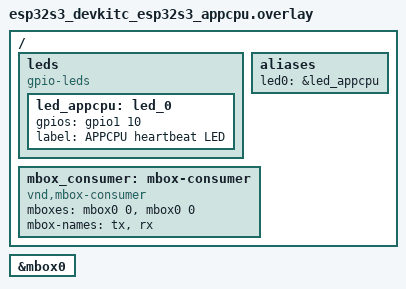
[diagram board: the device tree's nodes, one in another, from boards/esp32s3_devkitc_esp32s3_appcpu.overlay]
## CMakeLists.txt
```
cmake_minimum_required(VERSION 3.20.0)

find_package(Zephyr REQUIRED HINTS $ENV{ZEPHYR_BASE})
project(03_shm_race_appcpu)

target_sources(app PRIVATE src/main.c)
```

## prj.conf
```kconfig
# 03_SHM_RACE_LAB - core1 (appcpu) image
#
# No CONFIG_LOG / console here on purpose - see 01_HELLO_DUALCORE_LAB's
# doc for why (no UART console support on the appcpu image in Zephyr yet).
# This core proves what it's doing entirely through its heartbeat LED.
#
# NOTE: &ipm0 is intentionally left DISABLED - see prj.conf in the procpu
# app for why (only one of ipm0/mbox0 is ever enabled per lab).

CONFIG_GPIO=y
CONFIG_MBOX=y
```

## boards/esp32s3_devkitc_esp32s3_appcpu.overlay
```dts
/*
 * Overlay for 03_SHM_RACE_LAB - core1 (appcpu) image
 *
 * Reuses this series' GPIO42 "led0" heartbeat LED convention (see Lab 01).
 * See the procpu overlay in this same lab for why no new devicetree node
 * is needed for shared memory (ipmmem0 reuse) and why only &mbox0 (not
 * &ipm0) is enabled here.
 */

#include <zephyr/dt-bindings/gpio/gpio.h>

/ {
    leds {
        compatible = "gpio-leds";
        led_appcpu: led_0 {
            gpios = <&gpio1 10 GPIO_ACTIVE_HIGH>;
            label = "APPCPU heartbeat LED";
        };
    };

    aliases {
        led0 = &led_appcpu;
    };

    mbox_consumer: mbox-consumer {
        compatible = "vnd,mbox-consumer";
        mboxes = <&mbox0 0>, <&mbox0 0>;
        mbox-names = "tx", "rx";
    };
};

&mbox0 {
    status = "okay";
};
```

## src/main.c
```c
/*
 * main.c - 03_SHM_RACE_LAB (core1 / appcpu image)
 *
 * No console here (see 01_HELLO_DUALCORE_LAB's doc for why) - this core's
 * only visible output is its heartbeat LED (GPIO42):
 *
 *   - Normally blinks at a steady 200ms rate, same as Labs 01/02.
 *   - Every time it finishes "processing" one backlog item (see below), it
 *     does a quick double-flash before returning to its normal blink.
 *
 * The actual lesson of this lab happens where you can't see it directly on
 * this core (no console) but CAN see it in procpu's serial log: this core
 * deliberately processes backlog items more slowly (PROCESS_PERIOD_MS)
 * than procpu sends them (SEND_PERIOD_MS in the procpu image), so a
 * backlog builds up. An atomic pending-counter (see "pending" below) makes
 * sure every single doorbell procpu rings is still *counted* even while
 * this core is busy - but because procpu keeps overwriting the SAME
 * shared-memory slot with newer values the whole time, by the time this
 * core gets around to reading it, several intermediate values are already
 * gone for good. That gap is the point: counting notifications correctly
 * (atomic_t) is not the same problem as not losing the DATA that came with
 * each one - see the doc.
 */

#include <zephyr/kernel.h>
#include <zephyr/drivers/gpio.h>
#include <zephyr/drivers/mbox.h>
#include <zephyr/sys/atomic.h>

#include "shared_mem.h"

static const struct gpio_dt_spec led = GPIO_DT_SPEC_GET(DT_ALIAS(led0), gpios);

static const struct mbox_dt_spec tx_channel = MBOX_DT_SPEC_GET(DT_PATH(mbox_consumer), tx);
static const struct mbox_dt_spec rx_channel = MBOX_DT_SPEC_GET(DT_PATH(mbox_consumer), rx);

#define BLINK_PERIOD_MS       200
#define REACT_FLASH_PERIOD_MS 80
#define REACT_FLASH_EDGES     4 /* 4 edges = 2 full on/off flashes */

/* Deliberately slower than procpu's SEND_PERIOD_MS (200ms) - this gap is
 * what causes the backlog / lost-values race this lab demonstrates.
 */
#define PROCESS_PERIOD_MS 350
#define POLL_PERIOD_MS    10

/*
 * Incremented from ISR context on every doorbell from procpu. See the
 * procpu image's main.c for why atomic_t (not a plain bool/int) matters
 * here: it guarantees this core eventually finds out about and processes
 * every single doorbell, even ones that arrive while it is still busy
 * with an earlier one.
 */
static atomic_t pending = ATOMIC_INIT(0);

static void doorbell_from_procpu(const struct device *dev, mbox_channel_id_t channel_id,
				  void *user_data, struct mbox_msg *data)
{
	ARG_UNUSED(dev);
	ARG_UNUSED(channel_id);
	ARG_UNUSED(user_data);
	ARG_UNUSED(data);

	atomic_inc(&pending);
}

int main(void)
{
	if (!gpio_is_ready_dt(&led)) {
		return -1;
	}

	if (gpio_pin_configure_dt(&led, GPIO_OUTPUT_INACTIVE)) {
		return -1;
	}

	mbox_register_callback_dt(&rx_channel, doorbell_from_procpu, NULL);
	mbox_set_enabled_dt(&rx_channel, true);

	bool led_state = false;
	int64_t next_toggle = k_uptime_get() + BLINK_PERIOD_MS;
	int64_t next_process = 0; /* ready to process immediately */
	int reaction_edges_remaining = 0;
	uint32_t drained_count = 0;

	volatile struct p2a_payload *p2a = (volatile struct p2a_payload *)SHM_P2A_ADDR;
	volatile struct a2p_payload *a2p = (volatile struct a2p_payload *)SHM_A2P_ADDR;

	while (1) {
		int64_t now = k_uptime_get();

		/*
		 * Process at most one backlog item per PROCESS_PERIOD_MS,
		 * without ever blocking this loop - the LED heartbeat below
		 * keeps running on its own independent schedule regardless
		 * of backlog size.
		 */
		if (now >= next_process && atomic_get(&pending) > 0) {
			atomic_dec(&pending);
			drained_count++;

			/*
			 * Read whatever value happens to be in shared memory
			 * right now - NOT necessarily the value that was
			 * current when THIS particular doorbell was rung,
			 * since procpu may have already overwritten it one or
			 * more times since then.
			 */
			uint32_t seen_seq = p2a->seq;

			a2p->drained_count = drained_count;
			a2p->last_seen_seq = seen_seq;
			mbox_send_dt(&tx_channel, NULL);

			reaction_edges_remaining = REACT_FLASH_EDGES;
			next_process = now + PROCESS_PERIOD_MS;
		}

		if (reaction_edges_remaining > 0) {
			if (now >= next_toggle) {
				led_state = !led_state;
				gpio_pin_set_dt(&led, led_state);
				reaction_edges_remaining--;
				next_toggle = now + REACT_FLASH_PERIOD_MS;
			}
		} else if (now >= next_toggle) {
			led_state = !led_state;
			gpio_pin_set_dt(&led, led_state);
			next_toggle = now + BLINK_PERIOD_MS;
		}

		k_msleep(POLL_PERIOD_MS);
	}

	return 0;
}
```

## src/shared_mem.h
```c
/*
 * shared_mem.h - 03_SHM_RACE_LAB
 *
 * Describes the raw memory layout this lab uses inside ipmmem0, the 1KB
 * SRAM block (physical address 0x3fce5000) that the SoC devicetree already
 * reserves as &ipm0/&mbox0's own private message-copy scratch buffer (see
 * the "shared-memory"/"shared-memory-size" properties on those nodes in
 * Zephyr's esp32s3_common.dtsi). This lab reuses that exact block instead
 * of asking for a brand-new reserved-memory region, because every
 * mbox_send_dt() call this lab makes always passes a NULL payload (a pure
 * signal, same as 02_MBOX_DOORBELL_LAB) - so the mbox0 driver's own
 * memcpy into this buffer (drivers/mbox/mbox_esp32.c) is never triggered,
 * and the whole block is free for this lab's own use. See the doc for the
 * full reasoning.
 *
 * This file is intentionally duplicated byte-for-byte between src/ and
 * remote/src/ rather than shared through a common include path, because
 * procpu and appcpu are two completely separate Zephyr applications
 * (separate CMakeLists.txt / project() calls) built for two different
 * boards - keeping one small header in sync by hand is simpler here than
 * wiring up a shared include directory between them. If you edit this
 * file, edit both copies.
 */

#ifndef SHARED_MEM_H_
#define SHARED_MEM_H_

#include <zephyr/devicetree.h>
#include <stdint.h>

/* Base address/size of the reused ipmmem0 block, read directly from the
 * devicetree node - no application-defined devicetree node is needed for
 * this, since ipmmem0 is already declared (unconditionally) at the SoC
 * level and its "reg" property is readable via its label regardless of
 * whether &ipm0/&mbox0 are enabled. */
#define SHM_BASE (DT_REG_ADDR(DT_NODELABEL(ipmmem0)))
#define SHM_SIZE (DT_REG_SIZE(DT_NODELABEL(ipmmem0)))

/* mbox0's own driver splits this same 1KB block into two halves, one per
 * direction (see pro_cpu_shm/app_cpu_shm in drivers/mbox/mbox_esp32.c).
 * We mirror that same split for our own traffic, purely for symmetry. */
#define SHM_HALF_SIZE (SHM_SIZE / 2)

/* procpu writes here, appcpu reads (procpu -> appcpu) */
#define SHM_P2A_ADDR (SHM_BASE)
/* appcpu writes here, procpu reads (appcpu -> procpu) */
#define SHM_A2P_ADDR (SHM_BASE + SHM_HALF_SIZE)

/* procpu -> appcpu: one monotonically increasing sequence number per send */
struct p2a_payload {
	uint32_t seq;
};

/* appcpu -> procpu: what appcpu actually managed to process */
struct a2p_payload {
	uint32_t drained_count; /* total backlog items processed so far */
	uint32_t last_seen_seq; /* whatever seq value was in SHM_P2A_ADDR at
				  * the moment this item was processed - NOT
				  * guaranteed to include every value procpu
				  * ever wrote (see the doc)
				  */
};

#endif /* SHARED_MEM_H_ */
```
